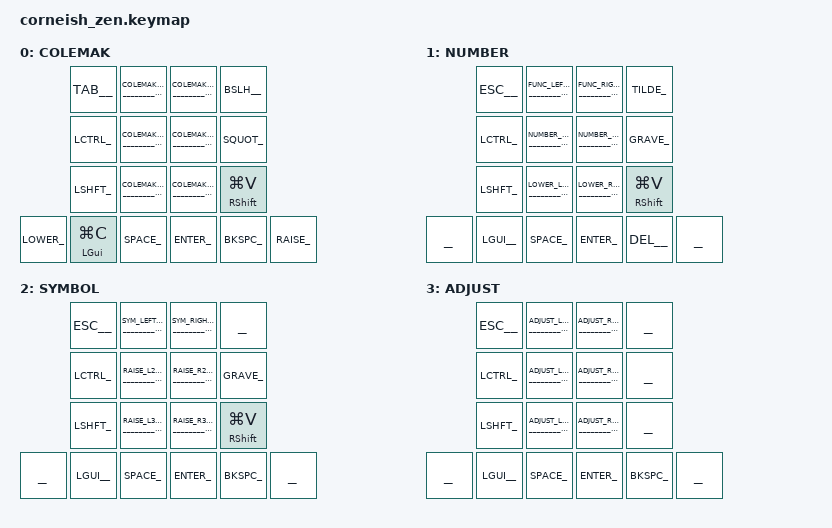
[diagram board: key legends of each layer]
#include <behaviors.dtsi>
#include <dt-bindings/zmk/keys.h>
#include <dt-bindings/zmk/bt.h>
#include "keycodes.h"
#include "wrappers.h"

// Hold-tap macros (require &hld behavior defined below)
#define _RSPST_ &hld RIGHT_SHIFT LG(V)  // Right Shift / Paste
#define _GCOPY_ &hld LGUI LG(C)         // GUI / Copy

/ {
    chosen {
        zmk,physical-layout = &foostan_corne_6col_layout;
        // zmk,physical-layout = &foostan_corne_5col_layout;
    };
};

/ {
        conditional_layers {
                compatible = "zmk,conditional-layers";
                tri_layer {
                        if-layers = <1 2>;
                        then-layer = <3>;
                };
        };

        // Combos: press two adjacent keys simultaneously to trigger output
        // .-----------------------------------.   .-----------------------------------.
        // |     |     | W+F | F+P |     |     |   |     | L+U |     |     |     |     |
        // |     |     | ESC |  +  |     |     |   |     |  =  |     |     |     |     |
        // |-----+-----+-----+-----+-----+-----|   |-----+-----+-----+-----+-----+-----|
        // |     | A+R | R+S | S+T |     |     |   |     | N+E | E+I | I+O |     |     |
        // |     | TAB |  _  | SPC |     |     |   |     | ENT |  -  | BSP |     |     |
        // |-----+-----+-----+-----+-----+-----|   |-----+-----+-----+-----+-----+-----|
        // |     |     |     |     |     |     |   |     | H+, |     |     |     |     |
        // |     |     |     |     |     |     |   |     |  :  |     |     |     |     |
        // '-----------------------------------'   '-----------------------------------'
        //
        // Key positions:
        //  0   1   2   3   4   5       6   7   8   9  10  11
        // 12  13  14  15  16  17      18  19  20  21  22  23
        // 24  25  26  27  28  29      30  31  32  33  34  35
        //             36  37  38      39  40  41
        combos {
                compatible = "zmk,combos";

                // Programming symbols
                combo_underscore { timeout-ms = <40>; key-positions = <14 15>; bindings = <&kp UNDER>; };      // R + S
                combo_minus      { timeout-ms = <40>; key-positions = <20 21>; bindings = <&kp MINUS>; };      // E + I
                combo_colon      { timeout-ms = <40>; key-positions = <31 32>; bindings = <&kp COLON>; };      // H + ,
                combo_equal      { timeout-ms = <40>; key-positions = <7 8>;   bindings = <&kp EQUAL>; };      // L + U
                combo_plus       { timeout-ms = <40>; key-positions = <3 4>;   bindings = <&kp PLUS>; };       // F + P

                // Navigation
                combo_enter      { timeout-ms = <40>; key-positions = <19 20>; bindings = <&kp ENTER>; };      // N + E
                combo_space      { timeout-ms = <40>; key-positions = <15 16>; bindings = <&kp SPACE>; };      // S + T
                combo_backspace  { timeout-ms = <40>; key-positions = <21 22>; bindings = <&kp BACKSPACE>; };  // I + O
                combo_esc        { timeout-ms = <30>; key-positions = <2 3>;   bindings = <&kp ESC>; };        // W + F
                combo_tab        { timeout-ms = <40>; key-positions = <13 14>; bindings = <&kp TAB>; };        // A + R
        };

        behaviors {
                as: auto_shift {
                        compatible = "zmk,behavior-hold-tap";
                        label = "AUTO_SHIFT";
                        #binding-cells = <2>;
                        tapping-term-ms = <220>;
                        quick-tap-ms = <0>;
                        flavor = "tap-preferred";
                        bindings = <&kp>, <&kp>;
                };
                hld: hold_tap {
                        compatible = "zmk,behavior-hold-tap";
                        label = "HOLD_TAP";
                        #binding-cells = <2>;
                        tapping-term-ms = <180>;
                        quick-tap-ms = <0>;
                        flavor = "tap-preferred";
                        bindings = <&kp>, <&kp>;
                };
        };

        keymap {
                compatible = "zmk,keymap";

                default_layer {
                        display-name = "COLEMAK";
                        // -------------------------------------------     -------------------------------------------
                        // |  TAB |   Q  |   W  |   F  |   P  |   B  |     |   J  |   L  |   U  |   Y  |   ;  |  \   |
                        // |LCTRL |   A  |   R  |   S  |   T  |   G  |     |   M  |   N  |   E  |   I  |   O  |  '   |
                        // |LSHFT |   Z  |   X  |   C  |   D  |   V  |     |   K  |   H  |   ,  |   .  |   /  |RSH/PS|
                        // `-----------------------------------------/     \-----------------------------------------'
                        //                      | LWR  |GUI/CP| SPC  |     | ENT  | BSPC |RAISE |
                        //                      ----------------------     ----------------------
                        bindings = <
                        __TAB__ _________________COLEMAK_L1________________  _________________COLEMAK_R1________________ _BSLH__
                        _LCTRL_ _________________COLEMAK_L2________________  _________________COLEMAK_R2________________ _SQUOT_
                        _LSHFT_ _________________COLEMAK_L3________________  _________________COLEMAK_R3________________ _RSPST_
                                          _LOWER_  _GCOPY_  _SPACE_  _ENTER_  _BKSPC_  _RAISE_
                        >;
                };

                lower_layer {
                        display-name = "NUMBER";
                        // -------------------------------------------     -------------------------------------------
                        // |ESC   |  F1  |  F2  |  F3  |  F4  |  F5  |     |  F6  |  F7  |  F8  |  F9  | F10  |   ~  |
                        // |LCTRL |   1  |   2  |   3  |   4  |   5  |     |   6  |   7  |   8  |   9  |   0  |   `  |
                        // |LSHFT |      |      |      |  OPT |      |     |  _   |  +   | "|"  |   {  |   }  |RSH/PS|
                        // `-----------------------------------------/     \-----------------------------------------'
                        //                      |      |  GUI | SPC  |     | ENT  | DEL  |      |
                        //                      ----------------------     ----------------------
                        bindings = <
                        __ESC__ _________________FUNC_LEFT_________________  _________________FUNC_RIGHT________________ _TILDE_
                        _LCTRL_ ________________NUMBER_LEFT________________  ________________NUMBER_RIGHT_______________ _GRAVE_
                        _LSHFT_ _________________LOWER_L3__________________  _________________LOWER_R3__________________ _RSPST_
                                                  _______  _LGUI__  _SPACE_  _ENTER_  __DEL__  _______
                        >;
                };

                raise_layer {
                        display-name = "SYMBOL";
                        // -------------------------------------------     -------------------------------------------
                        // | ESC  |  !   |  @   |  #   |  $   |  %   |     |  ^   |  &   |  *   |  (   |  )   |      |
                        // |LCTRL |      |      | PLAY | PREV | NEXT |     |      | left |  up  | down |right |  `   |
                        // |LSHFT |      |      | MUTE |VOLDN |VOLUP |     |  -   |  =   |      |  [   |  ]   |RSH/PS|
                        // `-----------------------------------------/     \-----------------------------------------'
                        //                      |      |  GUI | SPC  |     | ENT  | BSPC |      |
                        //                      ----------------------     ----------------------
                        bindings = <
                        __ESC__ _________________SYM_LEFT__________________  _________________SYM_RIGHT_________________ _______
                        _LCTRL_ _________________RAISE_L2__________________  _________________RAISE_R2__________________ _GRAVE_
                        _LSHFT_ _________________RAISE_L3__________________  _________________RAISE_R3__________________ _RSPST_
                                                  _______  _LGUI__  _SPACE_  _ENTER_  _BKSPC_  _______
                        >;
                };

                adjust_layer {
                        display-name = "ADJUST";
                        // -------------------------------------------     -------------------------------------------
                        // | ESC  | F11  | F12  |      |      |      |     |SCRSH | HOME | END  |      |      |      |
                        // |LCTRL | BT0  | BT1  | BT2  |      |      |     |DSK_L |MCTRL |EXPOSE|      |      |      |
                        // |LSHFT |BTCLR |      |      |      |      |     |DSK_R | PGDN | PGUP |      |      |      |
                        // `-----------------------------------------/     \-----------------------------------------'
                        //                      |      |  GUI | SPC  |     | ENT  | BSPC |      |
                        //                      ----------------------     ----------------------
                        bindings = <
                        __ESC__ _________________ADJUST_L1_________________  _________________ADJUST_R1_________________ _______
                        _LCTRL_ _________________ADJUST_L2_________________  _________________ADJUST_R2_________________ _______
                        _LSHFT_ _________________ADJUST_L3_________________  _________________ADJUST_R3_________________ _______
                                                  _______  _LGUI__  _SPACE_  _ENTER_  _BKSPC_  _______
                        >;
                };
        };
};
